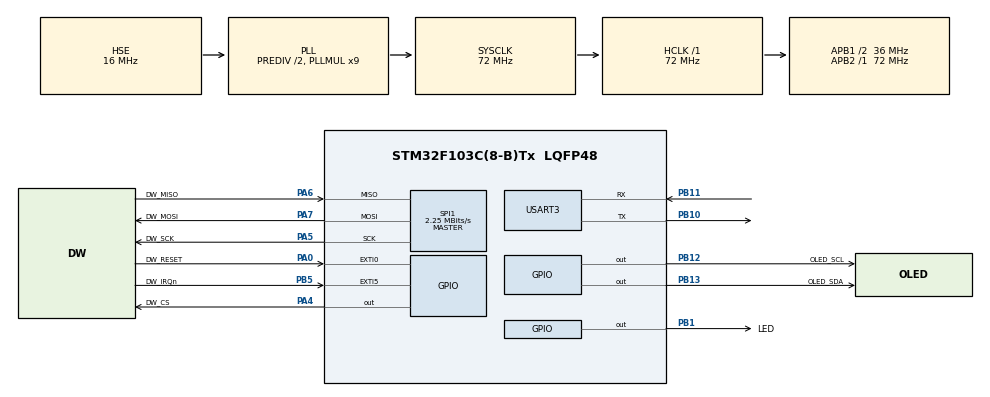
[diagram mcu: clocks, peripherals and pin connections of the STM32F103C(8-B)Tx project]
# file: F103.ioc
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FREERTOS.Tasks01=TaskShell,3,128,StartTaskShell,Default,NULL,Dynamic,NULL,NULL;TaskLED,-3,64,StartTaskLED,Default,NULL,Dynamic,NULL,NULL
FREERTOS.configMINIMAL_STACK_SIZE=64
Mcu.Family=STM32F1
Mcu.Name=STM32F103C(8-B)Tx
Mcu.Package=LQFP48
NVIC.EXTI0_IRQn=true\:5\:0\:true\:false\:true\:true\:true\:true
NVIC.EXTI9_5_IRQn=true\:5\:0\:true\:false\:true\:true\:true\:true
NVIC.PriorityGroup=NVIC_PRIORITYGROUP_4
NVIC.TIM3_IRQn=true\:5\:0\:false\:false\:true\:true\:true\:true
NVIC.TIM4_IRQn=true\:15\:0\:false\:false\:true\:false\:false\:true
NVIC.TimeBase=TIM4_IRQn
NVIC.TimeBaseIP=TIM4
NVIC.USART3_IRQn=true\:5\:0\:false\:false\:true\:true\:true\:true
PA0-WKUP.GPIO_Label=DW_RESET
PA0-WKUP.Signal=GPXTI0
PA13.GPIO_Label=SYS_SWDIO
PA13.Mode=Serial_Wire
PA13.Signal=SYS_JTMS-SWDIO
PA14.GPIO_Label=SYS_SWCLK
PA14.Mode=Serial_Wire
PA14.Signal=SYS_JTCK-SWCLK
PA4.GPIO_Label=DW_CS
PA4.GPIO_Speed=GPIO_SPEED_FREQ_HIGH
PA4.PinState=GPIO_PIN_SET
PA4.Signal=GPIO_Output
PA5.GPIO_Label=DW_SCK
PA5.Mode=Full_Duplex_Master
PA5.Signal=SPI1_SCK
PA6.GPIO_Label=DW_MISO
PA6.Mode=Full_Duplex_Master
PA6.Signal=SPI1_MISO
PA7.GPIO_Label=DW_MOSI
PA7.Mode=Full_Duplex_Master
PA7.Signal=SPI1_MOSI
PB1.GPIO_Label=LED
PB1.GPIO_PuPd=GPIO_PULLUP
PB1.GPIO_Speed=GPIO_SPEED_FREQ_HIGH
PB1.PinState=GPIO_PIN_SET
PB1.Signal=GPIO_Output
PB10.Mode=Asynchronous
PB10.Signal=USART3_TX
PB11.Mode=Asynchronous
PB11.Signal=USART3_RX
PB12.GPIO_Label=OLED_SCL
PB12.GPIO_ModeDefaultOutputPP=GPIO_MODE_OUTPUT_PP
PB12.GPIO_PuPd=GPIO_NOPULL
PB12.GPIO_Speed=GPIO_SPEED_FREQ_HIGH
PB12.PinState=GPIO_PIN_SET
PB12.Signal=GPIO_Output
PB13.GPIO_Label=OLED_SDA
PB13.GPIO_ModeDefaultOutputPP=GPIO_MODE_OUTPUT_PP
PB13.GPIO_PuPd=GPIO_NOPULL
PB13.GPIO_Speed=GPIO_SPEED_FREQ_HIGH
PB13.PinState=GPIO_PIN_SET
PB13.Signal=GPIO_Output
PB5.GPIO_Label=DW_IRQn
PB5.GPIO_PuPd=GPIO_PULLDOWN
PB5.Signal=GPXTI5
PD0-OSC_IN.Mode=HSE-External-Oscillator
PD0-OSC_IN.Signal=RCC_OSC_IN
PD1-OSC_OUT.Mode=HSE-External-Oscillator
PD1-OSC_OUT.Signal=RCC_OSC_OUT
ProjectManager.HeapSize=0x200
ProjectManager.StackSize=0x400
ProjectManager.TargetToolchain=MDK-ARM V5.32
RCC.AHBFreq_Value=72000000
RCC.APB1CLKDivider=RCC_HCLK_DIV2
RCC.APB1Freq_Value=36000000
RCC.APB1TimFreq_Value=72000000
RCC.APB2Freq_Value=72000000
RCC.APB2TimFreq_Value=72000000
RCC.HCLKFreq_Value=72000000
RCC.HSEDivPLL=RCC_HSE_PREDIV_DIV2
RCC.HSE_VALUE=16000000
RCC.PLLMUL=RCC_PLL_MUL9
RCC.PLLSourceVirtual=RCC_PLLSOURCE_HSE
RCC.SYSCLKFreq_VALUE=72000000
RCC.SYSCLKSource=RCC_SYSCLKSOURCE_PLLCLK
RCC.USBFreq_Value=72000000
SPI1.BaudRatePrescaler=SPI_BAUDRATEPRESCALER_32
SPI1.CRCCalculation=SPI_CRCCALCULATION_DISABLE
SPI1.CalculateBaudRate=2.25 MBits/s
SPI1.Direction=SPI_DIRECTION_2LINES
SPI1.Mode=SPI_MODE_MASTER
SPI1.VirtualType=VM_MASTER
TIM3.Prescaler=71
USART3.VirtualMode=VM_ASYNC
VP_FREERTOS_VS_CMSIS_V1.Mode=CMSIS_V1
VP_SYS_VS_tim4.Mode=TIM4
VP_TIM3_VS_ClockSourceINT.Mode=Internal
board=custom

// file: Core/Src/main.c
/* USER CODE BEGIN Header */
/**
  ******************************************************************************
  * @file           : main.c
  * @brief          : Main program body
  ******************************************************************************
  * @attention
  *
  * Copyright (c) 2022 STMicroelectronics.
  * All rights reserved.
  *
  * This software is licensed under terms that can be found in the LICENSE file
  * in the root directory of this software component.
  * If no LICENSE file comes with this software, it is provided AS-IS.
  *
  ******************************************************************************
  */
/* USER CODE END Header */
#include "main.h"
#include "cmsis_os.h"
#include "spi.h"
#include "tim.h"
#include "usart.h"
#include "gpio.h"

/* USER CODE BEGIN Includes */
#include "oled.h"
#include "usrcmd.h"
/* USER CODE END Includes */

void SystemClock_Config(void);
void MX_FREERTOS_Init(void);

int main(void)
{

  /* MCU Configuration--------------------------------------------------------*/

  /* Reset of all peripherals, Initializes the Flash interface and the Systick. */
  HAL_Init();

  /* Configure the system clock */
  SystemClock_Config();

  /* Initialize all configured peripherals */
  MX_GPIO_Init();
  MX_SPI1_Init();
  MX_TIM3_Init();
  MX_USART3_UART_Init();
  /* USER CODE BEGIN 2 */
  HAL_Delay(500);
  OLED_Init();
  NTShell_Init();
  /* USER CODE END 2 */

  /* Call init function for freertos objects (in freertos.c) */
  MX_FREERTOS_Init();
  /* Start scheduler */
  osKernelStart();

  /* We should never get here as control is now taken by the scheduler */
  /* Infinite loop */
  while (1)
  {

  }
}

void SystemClock_Config(void)
{
  RCC_OscInitTypeDef RCC_OscInitStruct = {0};
  RCC_ClkInitTypeDef RCC_ClkInitStruct = {0};

  /** Initializes the RCC Oscillators according to the specified parameters
  * in the RCC_OscInitTypeDef structure.
  */
  RCC_OscInitStruct.OscillatorType = RCC_OSCILLATORTYPE_HSE;
  RCC_OscInitStruct.HSEState = RCC_HSE_ON;
  RCC_OscInitStruct.HSEPredivValue = RCC_HSE_PREDIV_DIV2;
  RCC_OscInitStruct.HSIState = RCC_HSI_ON;
  RCC_OscInitStruct.PLL.PLLState = RCC_PLL_ON;
  RCC_OscInitStruct.PLL.PLLSource = RCC_PLLSOURCE_HSE;
  RCC_OscInitStruct.PLL.PLLMUL = RCC_PLL_MUL9;
  if (HAL_RCC_OscConfig(&RCC_OscInitStruct) != HAL_OK)
  {
    Error_Handler();
  }
  /** Initializes the CPU, AHB and APB buses clocks
  */
  RCC_ClkInitStruct.ClockType = RCC_CLOCKTYPE_HCLK|RCC_CLOCKTYPE_SYSCLK
                              |RCC_CLOCKTYPE_PCLK1|RCC_CLOCKTYPE_PCLK2;
  RCC_ClkInitStruct.SYSCLKSource = RCC_SYSCLKSOURCE_PLLCLK;
  RCC_ClkInitStruct.AHBCLKDivider = RCC_SYSCLK_DIV1;
  RCC_ClkInitStruct.APB1CLKDivider = RCC_HCLK_DIV2;
  RCC_ClkInitStruct.APB2CLKDivider = RCC_HCLK_DIV1;

  if (HAL_RCC_ClockConfig(&RCC_ClkInitStruct, FLASH_LATENCY_2) != HAL_OK)
  {
    Error_Handler();
  }
}

void HAL_TIM_PeriodElapsedCallback(TIM_HandleTypeDef *htim)
{
  if (htim->Instance == TIM4) {
    HAL_IncTick();
  }
}

void Error_Handler(void)
{
  __disable_irq();
  while (1)
  {
  }
}

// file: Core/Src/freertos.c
/* USER CODE BEGIN Header */
/**
  ******************************************************************************
  * File Name          : freertos.c
  * Description        : Code for freertos applications
  ******************************************************************************
  * @attention
  *
  * Copyright (c) 2022 STMicroelectronics.
  * All rights reserved.
  *
  * This software is licensed under terms that can be found in the LICENSE file
  * in the root directory of this software component.
  * If no LICENSE file comes with this software, it is provided AS-IS.
  *
  ******************************************************************************
  */
/* USER CODE END Header */

#include "FreeRTOS.h"
#include "task.h"
#include "main.h"
#include "cmsis_os.h"

/* USER CODE BEGIN Includes */
#include "usrcmd.h"
/* USER CODE END Includes */

osThreadId TaskShellHandle;
osThreadId TaskLEDHandle;

void StartTaskShell(void const * argument);
void StartTaskLED(void const * argument);

void MX_FREERTOS_Init(void); /* (MISRA C 2004 rule 8.1) */

/* GetIdleTaskMemory prototype (linked to static allocation support) */
void vApplicationGetIdleTaskMemory( StaticTask_t **ppxIdleTaskTCBBuffer, StackType_t **ppxIdleTaskStackBuffer, uint32_t *pulIdleTaskStackSize );

/* USER CODE BEGIN GET_IDLE_TASK_MEMORY */
static StaticTask_t xIdleTaskTCBBuffer;
static StackType_t xIdleStack[configMINIMAL_STACK_SIZE];

void vApplicationGetIdleTaskMemory( StaticTask_t **ppxIdleTaskTCBBuffer, StackType_t **ppxIdleTaskStackBuffer, uint32_t *pulIdleTaskStackSize )
{
  *ppxIdleTaskTCBBuffer = &xIdleTaskTCBBuffer;
  *ppxIdleTaskStackBuffer = &xIdleStack[0];
  *pulIdleTaskStackSize = configMINIMAL_STACK_SIZE;
  /* place for user code */
}
/* USER CODE END GET_IDLE_TASK_MEMORY */

void MX_FREERTOS_Init(void) {

  /* Create the thread(s) */
  /* definition and creation of TaskShell */
  osThreadDef(TaskShell, StartTaskShell, osPriorityRealtime, 0, 128);
  TaskShellHandle = osThreadCreate(osThread(TaskShell), NULL);

  /* definition and creation of TaskLED */
  osThreadDef(TaskLED, StartTaskLED, osPriorityIdle, 0, 64);
  TaskLEDHandle = osThreadCreate(osThread(TaskLED), NULL);

}

void StartTaskShell(void const * argument)
{
  /* USER CODE BEGIN StartTaskShell */
  /* Infinite loop */
  for(;;)
  {
	NTShell_Processing();
    osDelay(1);
  }
  /* USER CODE END StartTaskShell */
}

void StartTaskLED(void const * argument)
{
  /* USER CODE BEGIN StartTaskLED */
  /* Infinite loop */
  for(;;)
  {
    osDelay(100);
  }
  /* USER CODE END StartTaskLED */
}
